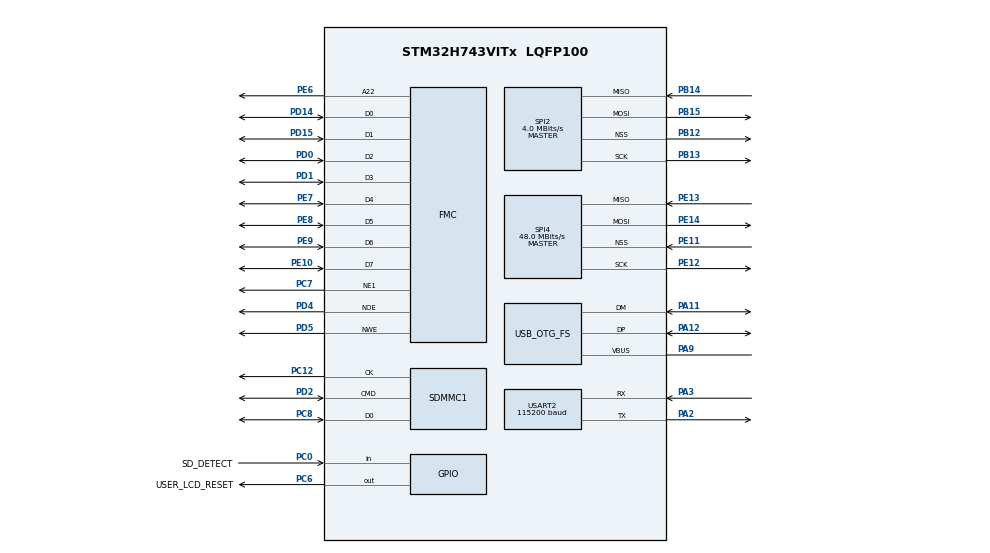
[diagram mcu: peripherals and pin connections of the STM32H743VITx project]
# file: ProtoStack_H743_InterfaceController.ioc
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CORTEX_M7.AccessPermission-Cortex_Memory_Protection_Unit_Region2_Settings=MPU_REGION_FULL_ACCESS
CORTEX_M7.AccessPermission-Cortex_Memory_Protection_Unit_Region3_Settings=MPU_REGION_FULL_ACCESS
CORTEX_M7.BaseAddress-Cortex_Memory_Protection_Unit_Region2_Settings=0x60000000
CORTEX_M7.BaseAddress-Cortex_Memory_Protection_Unit_Region3_Settings=0x24000000
CORTEX_M7.CPU_DCache=Enabled
CORTEX_M7.CPU_ICache=Enabled
CORTEX_M7.DisableExec-Cortex_Memory_Protection_Unit_Region3_Settings=MPU_INSTRUCTION_ACCESS_DISABLE
CORTEX_M7.Enable-Cortex_Memory_Protection_Unit_Region2_Settings=MPU_REGION_ENABLE
CORTEX_M7.Enable-Cortex_Memory_Protection_Unit_Region3_Settings=MPU_REGION_ENABLE
CORTEX_M7.IsBufferable-Cortex_Memory_Protection_Unit_Region2_Settings=MPU_ACCESS_BUFFERABLE
CORTEX_M7.IsBufferable-Cortex_Memory_Protection_Unit_Region3_Settings=MPU_ACCESS_BUFFERABLE
CORTEX_M7.IsShareable-Cortex_Memory_Protection_Unit_Region2_Settings=MPU_ACCESS_SHAREABLE
CORTEX_M7.IsShareable-Cortex_Memory_Protection_Unit_Region3_Settings=MPU_ACCESS_SHAREABLE
CORTEX_M7.MPU_Control=MPU_PRIVILEGED_DEFAULT
CORTEX_M7.Size-Cortex_Memory_Protection_Unit_Region2_Settings=MPU_REGION_SIZE_64MB
CORTEX_M7.Size-Cortex_Memory_Protection_Unit_Region3_Settings=MPU_REGION_SIZE_8KB
Dma.Request0=SPI2_RX
Dma.Request1=SPI2_TX
Dma.Request2=USART2_RX
Dma.Request3=USART2_TX
Dma.Request4=SPI4_RX
Dma.Request5=SPI4_TX
Dma.SPI2_RX.0.Direction=DMA_PERIPH_TO_MEMORY
Dma.SPI2_RX.0.EventEnable=DISABLE
Dma.SPI2_RX.0.FIFOMode=DMA_FIFOMODE_DISABLE
Dma.SPI2_RX.0.Instance=DMA1_Stream2
Dma.SPI2_RX.0.MemDataAlignment=DMA_MDATAALIGN_BYTE
Dma.SPI2_RX.0.MemInc=DMA_MINC_ENABLE
Dma.SPI2_RX.0.Mode=DMA_NORMAL
Dma.SPI2_RX.0.PeriphDataAlignment=DMA_PDATAALIGN_BYTE
Dma.SPI2_RX.0.PeriphInc=DMA_PINC_DISABLE
Dma.SPI2_RX.0.Polarity=HAL_DMAMUX_REQ_GEN_RISING
Dma.SPI2_RX.0.Priority=DMA_PRIORITY_LOW
Dma.SPI2_RX.0.RequestNumber=1
Dma.SPI2_RX.0.SignalID=NONE
Dma.SPI2_RX.0.SyncEnable=DISABLE
Dma.SPI2_RX.0.SyncPolarity=HAL_DMAMUX_SYNC_NO_EVENT
Dma.SPI2_RX.0.SyncRequestNumber=1
Dma.SPI2_RX.0.SyncSignalID=NONE
Dma.SPI2_TX.1.Direction=DMA_MEMORY_TO_PERIPH
Dma.SPI2_TX.1.EventEnable=DISABLE
Dma.SPI2_TX.1.FIFOMode=DMA_FIFOMODE_DISABLE
Dma.SPI2_TX.1.Instance=DMA1_Stream3
Dma.SPI2_TX.1.MemDataAlignment=DMA_MDATAALIGN_BYTE
Dma.SPI2_TX.1.MemInc=DMA_MINC_ENABLE
Dma.SPI2_TX.1.Mode=DMA_NORMAL
Dma.SPI2_TX.1.PeriphDataAlignment=DMA_PDATAALIGN_BYTE
Dma.SPI2_TX.1.PeriphInc=DMA_PINC_DISABLE
Dma.SPI2_TX.1.Polarity=HAL_DMAMUX_REQ_GEN_RISING
Dma.SPI2_TX.1.Priority=DMA_PRIORITY_LOW
Dma.SPI2_TX.1.RequestNumber=1
Dma.SPI2_TX.1.SignalID=NONE
Dma.SPI2_TX.1.SyncEnable=DISABLE
Dma.SPI2_TX.1.SyncPolarity=HAL_DMAMUX_SYNC_NO_EVENT
Dma.SPI2_TX.1.SyncRequestNumber=1
Dma.SPI2_TX.1.SyncSignalID=NONE
Dma.SPI4_RX.4.Direction=DMA_PERIPH_TO_MEMORY
Dma.SPI4_RX.4.EventEnable=DISABLE
Dma.SPI4_RX.4.FIFOMode=DMA_FIFOMODE_DISABLE
Dma.SPI4_RX.4.Instance=DMA1_Stream4
Dma.SPI4_RX.4.MemDataAlignment=DMA_MDATAALIGN_HALFWORD
Dma.SPI4_RX.4.MemInc=DMA_MINC_ENABLE
Dma.SPI4_RX.4.Mode=DMA_CIRCULAR
Dma.SPI4_RX.4.PeriphDataAlignment=DMA_PDATAALIGN_HALFWORD
Dma.SPI4_RX.4.PeriphInc=DMA_PINC_DISABLE
Dma.SPI4_RX.4.Polarity=HAL_DMAMUX_REQ_GEN_RISING
Dma.SPI4_RX.4.Priority=DMA_PRIORITY_LOW
Dma.SPI4_RX.4.RequestNumber=1
Dma.SPI4_RX.4.SignalID=NONE
Dma.SPI4_RX.4.SyncEnable=DISABLE
Dma.SPI4_RX.4.SyncPolarity=HAL_DMAMUX_SYNC_NO_EVENT
Dma.SPI4_RX.4.SyncRequestNumber=1
Dma.SPI4_RX.4.SyncSignalID=NONE
Dma.SPI4_TX.5.Direction=DMA_MEMORY_TO_PERIPH
Dma.SPI4_TX.5.EventEnable=DISABLE
Dma.SPI4_TX.5.FIFOMode=DMA_FIFOMODE_DISABLE
Dma.SPI4_TX.5.Instance=DMA1_Stream5
Dma.SPI4_TX.5.MemDataAlignment=DMA_MDATAALIGN_HALFWORD
Dma.SPI4_TX.5.MemInc=DMA_MINC_ENABLE
Dma.SPI4_TX.5.Mode=DMA_NORMAL
Dma.SPI4_TX.5.PeriphDataAlignment=DMA_PDATAALIGN_HALFWORD
Dma.SPI4_TX.5.PeriphInc=DMA_PINC_DISABLE
Dma.SPI4_TX.5.Polarity=HAL_DMAMUX_REQ_GEN_RISING
Dma.SPI4_TX.5.Priority=DMA_PRIORITY_LOW
Dma.SPI4_TX.5.RequestNumber=1
Dma.SPI4_TX.5.SignalID=NONE
Dma.SPI4_TX.5.SyncEnable=DISABLE
Dma.SPI4_TX.5.SyncPolarity=HAL_DMAMUX_SYNC_NO_EVENT
Dma.SPI4_TX.5.SyncRequestNumber=1
Dma.SPI4_TX.5.SyncSignalID=NONE
Dma.USART2_RX.2.Direction=DMA_PERIPH_TO_MEMORY
Dma.USART2_RX.2.EventEnable=DISABLE
Dma.USART2_RX.2.FIFOMode=DMA_FIFOMODE_DISABLE
Dma.USART2_RX.2.Instance=DMA1_Stream0
Dma.USART2_RX.2.MemDataAlignment=DMA_MDATAALIGN_BYTE
Dma.USART2_RX.2.MemInc=DMA_MINC_ENABLE
Dma.USART2_RX.2.Mode=DMA_CIRCULAR
Dma.USART2_RX.2.PeriphDataAlignment=DMA_PDATAALIGN_BYTE
Dma.USART2_RX.2.PeriphInc=DMA_PINC_DISABLE
Dma.USART2_RX.2.Polarity=HAL_DMAMUX_REQ_GEN_RISING
Dma.USART2_RX.2.Priority=DMA_PRIORITY_LOW
Dma.USART2_RX.2.RequestNumber=1
Dma.USART2_RX.2.SignalID=NONE
Dma.USART2_RX.2.SyncEnable=DISABLE
Dma.USART2_RX.2.SyncPolarity=HAL_DMAMUX_SYNC_NO_EVENT
Dma.USART2_RX.2.SyncRequestNumber=1
Dma.USART2_RX.2.SyncSignalID=NONE
Dma.USART2_TX.3.Direction=DMA_MEMORY_TO_PERIPH
Dma.USART2_TX.3.EventEnable=DISABLE
Dma.USART2_TX.3.FIFOMode=DMA_FIFOMODE_DISABLE
Dma.USART2_TX.3.Instance=DMA1_Stream1
Dma.USART2_TX.3.MemDataAlignment=DMA_MDATAALIGN_BYTE
Dma.USART2_TX.3.MemInc=DMA_MINC_ENABLE
Dma.USART2_TX.3.Mode=DMA_NORMAL
Dma.USART2_TX.3.PeriphDataAlignment=DMA_PDATAALIGN_BYTE
Dma.USART2_TX.3.PeriphInc=DMA_PINC_DISABLE
Dma.USART2_TX.3.Polarity=HAL_DMAMUX_REQ_GEN_RISING
Dma.USART2_TX.3.Priority=DMA_PRIORITY_LOW
Dma.USART2_TX.3.RequestNumber=1
Dma.USART2_TX.3.SignalID=NONE
Dma.USART2_TX.3.SyncEnable=DISABLE
Dma.USART2_TX.3.SyncPolarity=HAL_DMAMUX_SYNC_NO_EVENT
Dma.USART2_TX.3.SyncRequestNumber=1
Dma.USART2_TX.3.SyncSignalID=NONE
FATFS.BSP.number=1
FATFS._FS_RPATH=2
FATFS._USE_EXPAND=1
FATFS._USE_FIND=1
FATFS._USE_LFN=3
FATFS0.BSP.STBoard=false
FATFS0.BSP.api=Unknown
FATFS0.BSP.instance=PC0
FATFS0.BSP.ip=GPIO
FATFS0.BSP.mode=Input
FATFS0.BSP.name=Detect_SDIO
FATFS0.BSP.solution=PC0
FMC.AddressSetupTime1=8
FMC.BusTurnAroundDuration1=8
FMC.DataSetupTime1=16
FREERTOS.Queues01=UpdateGUIQueue,16,struct UPDATEGUIQUEUE_OBJ_t,0,Dynamic,NULL,NULL;ReadWriteUIQueue,16,struct READWRITEUIQUEUE_OBJ_t,0,Dynamic,NULL,NULL;UpdateAudioParamsQueue,16,struct UPDATEAUDIOPARAMS_OBJ_t,0,Dynamic,NULL,NULL
FREERTOS.Tasks01=defaultTask,24,128,StartDefaultTask,Default,NULL,Dynamic,NULL,NULL;TouchGFXUpdateTask,24,1024,StartTouchGFXUpdateTask,Default,NULL,Dynamic,NULL,NULL;VSyncTask,24,512,StartVSyncTask,Default,NULL,Dynamic,NULL,NULL;ReadWriteUITask,24,512,StartReadWriteUITask,Default,NULL,Dynamic,NULL,NULL;UpdateFromUITask,24,512,StartUpdateFromUITask,Default,NULL,Dynamic,NULL,NULL
FREERTOS.configGENERATE_RUN_TIME_STATS=1
FREERTOS.configMAX_TASK_NAME_LEN=32
FREERTOS.configRECORD_STACK_HIGH_ADDRESS=1
FREERTOS.configTOTAL_HEAP_SIZE=16384
FREERTOS.configUSE_NEWLIB_REENTRANT=1
FREERTOS.configUSE_STATS_FORMATTING_FUNCTIONS=1
Mcu.Family=STM32H7
Mcu.Name=STM32H743VITx
Mcu.Package=LQFP100
NVIC.DMA1_Stream0_IRQn=true\:5\:0\:false\:false\:true\:true\:false\:true\:true
NVIC.DMA1_Stream1_IRQn=true\:5\:0\:false\:false\:true\:true\:false\:true\:true
NVIC.DMA1_Stream2_IRQn=true\:5\:0\:false\:false\:true\:true\:false\:true\:true
NVIC.DMA1_Stream3_IRQn=true\:5\:0\:false\:false\:true\:true\:false\:true\:true
NVIC.DMA1_Stream4_IRQn=true\:5\:0\:false\:false\:true\:true\:false\:true\:true
NVIC.DMA1_Stream5_IRQn=true\:5\:0\:false\:false\:true\:true\:false\:true\:true
NVIC.OTG_FS_IRQn=true\:5\:0\:false\:false\:true\:true\:true\:true\:true
NVIC.PriorityGroup=NVIC_PRIORITYGROUP_4
NVIC.SDMMC1_IRQn=true\:5\:0\:false\:false\:true\:true\:true\:true\:true
NVIC.SPI2_IRQn=true\:5\:0\:false\:false\:true\:true\:true\:true\:true
NVIC.SPI4_IRQn=true\:5\:0\:false\:false\:true\:true\:true\:true\:true
NVIC.TIM2_IRQn=true\:0\:0\:true\:false\:true\:false\:false\:true\:true
NVIC.TIM6_DAC_IRQn=true\:5\:0\:false\:false\:true\:true\:true\:true\:true
NVIC.TimeBase=TIM2_IRQn
NVIC.TimeBaseIP=TIM2
NVIC.USART2_IRQn=true\:15\:0\:true\:false\:true\:true\:true\:true\:true
PA11.GPIO_Speed=GPIO_SPEED_FREQ_VERY_HIGH
PA11.Mode=Device_Only
PA11.Signal=USB_OTG_FS_DM
PA12.GPIO_Speed=GPIO_SPEED_FREQ_VERY_HIGH
PA12.Mode=Device_Only
PA12.Signal=USB_OTG_FS_DP
PA13\ (JTMS/SWDIO).Mode=Trace_Asynchronous_SW
PA13\ (JTMS/SWDIO).Signal=DEBUG_JTMS-SWDIO
PA14\ (JTCK/SWCLK).Mode=Trace_Asynchronous_SW
PA14\ (JTCK/SWCLK).Signal=DEBUG_JTCK-SWCLK
PA2.GPIO_Speed=GPIO_SPEED_FREQ_LOW
PA2.Mode=Asynchronous
PA2.Signal=USART2_TX
PA3.GPIO_Speed=GPIO_SPEED_FREQ_LOW
PA3.Mode=Asynchronous
PA3.Signal=USART2_RX
PA9.Mode=Activate_VBUS
PA9.Signal=USB_OTG_FS_VBUS
PB12.Mode=NSS_Signal_Hard_Output
PB12.Signal=SPI2_NSS
PB13.Mode=Full_Duplex_Master
PB13.Signal=SPI2_SCK
PB14.Mode=Full_Duplex_Master
PB14.Signal=SPI2_MISO
PB15.Mode=Full_Duplex_Master
PB15.Signal=SPI2_MOSI
PB3\ (JTDO/TRACESWO).Mode=Trace_Asynchronous_SW
PB3\ (JTDO/TRACESWO).Signal=DEBUG_JTDO-SWO
PC0.GPIO_Label=SD_DETECT
PC0.GPIO_PuPd=GPIO_PULLUP
PC0.Signal=GPIO_Input
PC12.GPIO_PuPd=GPIO_PULLUP
PC12.Mode=SD_1_bit
PC12.Signal=SDMMC1_CK
PC6.GPIO_Label=USER_LCD_RESET
PC6.PinState=GPIO_PIN_SET
PC6.Signal=GPIO_Output
PC7.Mode=NorPsramChipSelect1_1
PC7.Signal=FMC_NE1
PC8.GPIO_PuPd=GPIO_PULLUP
PC8.Mode=SD_1_bit
PC8.Signal=SDMMC1_D0
PD0.Signal=FMC_D2_DA2
PD1.Signal=FMC_D3_DA3
PD14.Signal=FMC_D0_DA0
PD15.Signal=FMC_D1_DA1
PD2.GPIO_PuPd=GPIO_PULLUP
PD2.Mode=SD_1_bit
PD2.Signal=SDMMC1_CMD
PD4.Signal=FMC_NOE
PD5.Signal=FMC_NWE
PD7.GPIO_Speed=GPIO_SPEED_FREQ_LOW
PD7.Signal=USART2_CK
PE10.Signal=FMC_D7_DA7
PE11.Mode=NSS_Signal_Hard_Input
PE11.Signal=SPI4_NSS
PE12.Mode=Full_Duplex_Master
PE12.Signal=SPI4_SCK
PE13.Mode=Full_Duplex_Master
PE13.Signal=SPI4_MISO
PE14.Mode=Full_Duplex_Master
PE14.Signal=SPI4_MOSI
PE6.Signal=FMC_A22
PE7.Signal=FMC_D4_DA4
PE8.Signal=FMC_D5_DA5
PE9.Signal=FMC_D6_DA6
PH0-OSC_IN\ (PH0).Mode=HSE-External-Oscillator
PH0-OSC_IN\ (PH0).Signal=RCC_OSC_IN
PH1-OSC_OUT\ (PH1).Mode=HSE-External-Oscillator
PH1-OSC_OUT\ (PH1).Signal=RCC_OSC_OUT
ProjectManager.HeapSize=0x400
ProjectManager.StackSize=0x800
ProjectManager.TargetToolchain=STM32CubeIDE
RCC.ADCFreq_Value=192000000
RCC.APB1Freq_Value=120000000
RCC.APB2Freq_Value=120000000
RCC.APB3Freq_Value=120000000
RCC.APB4Freq_Value=120000000
RCC.CortexFreq_Value=480000000
RCC.D1PPRE=RCC_APB3_DIV2
RCC.D2PPRE1=RCC_APB1_DIV2
RCC.D2PPRE2=RCC_APB2_DIV2
RCC.D3PPRE=RCC_APB4_DIV2
RCC.DIVM1=4
RCC.DIVM2=8
RCC.DIVM3=16
RCC.DIVN1=160
RCC.DIVN2=128
RCC.DIVN3=128
RCC.DIVQ1=20
RCC.HCLKFreq_Value=240000000
RCC.HPRE=RCC_HCLK_DIV2
RCC.HSE_VALUE=24000000
RCC.PLLSourceVirtual=RCC_PLLSOURCE_HSE
RCC.SPI123CLockSelection=RCC_SPI123CLKSOURCE_CLKP
RCC.SYSCLKFreq_VALUE=480000000
RCC.SYSCLKSource=RCC_SYSCLKSOURCE_PLLCLK
RCC.Spi45ClockSelection=RCC_SPI45CLKSOURCE_PLL3
RCC.USBCLockSelection=RCC_USBCLKSOURCE_HSI48
RCC.USBFreq_Value=48000000
SDMMC1.ClockDiv=1
SH.FMC_A22.0=FMC_A22,A22_1
SH.FMC_D0_DA0.0=FMC_D0,8b-d1
SH.FMC_D1_DA1.0=FMC_D1,8b-d1
SH.FMC_D2_DA2.0=FMC_D2,8b-d1
SH.FMC_D3_DA3.0=FMC_D3,8b-d1
SH.FMC_D4_DA4.0=FMC_D4,8b-d1
SH.FMC_D5_DA5.0=FMC_D5,8b-d1
SH.FMC_D6_DA6.0=FMC_D6,8b-d1
SH.FMC_D7_DA7.0=FMC_D7,8b-d1
SH.FMC_NOE.0=FMC_NOE,Lcd1
SH.FMC_NWE.0=FMC_NWE,Lcd1
SPI2.BaudRatePrescaler=SPI_BAUDRATEPRESCALER_16
SPI2.CalculateBaudRate=4.0 MBits/s
SPI2.DataSize=SPI_DATASIZE_8BIT
SPI2.Direction=SPI_DIRECTION_2LINES
SPI2.Mode=SPI_MODE_MASTER
SPI2.NSSPolarity=SPI_NSS_POLARITY_HIGH
SPI2.VirtualNSS=VM_NSSHARD
SPI2.VirtualType=VM_MASTER
SPI4.CalculateBaudRate=48.0 MBits/s
SPI4.DataSize=SPI_DATASIZE_16BIT
SPI4.Direction=SPI_DIRECTION_2LINES
SPI4.Mode=SPI_MODE_MASTER
SPI4.VirtualNSS=VM_NSSHARD
SPI4.VirtualType=VM_MASTER
STMicroelectronics.X-CUBE-TOUCHGFX.4.21.3.ApplicationCcGraphicsJjApplication=TouchGFXOoGenerator
STMicroelectronics.X-CUBE-TOUCHGFX.4.21.3.tgfx_address1=0x60000000
STMicroelectronics.X-CUBE-TOUCHGFX.4.21.3.tgfx_block_size=15360
STMicroelectronics.X-CUBE-TOUCHGFX.4.21.3.tgfx_buffering_strategy=Partial
STMicroelectronics.X-CUBE-TOUCHGFX.4.21.3.tgfx_custom_height=240
STMicroelectronics.X-CUBE-TOUCHGFX.4.21.3.tgfx_custom_width=320
STMicroelectronics.X-CUBE-TOUCHGFX.4.21.3.tgfx_display_interface=disp_custom
STMicroelectronics.X-CUBE-TOUCHGFX.4.21.3.tgfx_hardware_accelerator=dma_none
STMicroelectronics.X-CUBE-TOUCHGFX.4.21.3.tgfx_location=By Address
STMicroelectronics.X-CUBE-TOUCHGFX.4.21.3.tgfx_number_of_blocks=4
STMicroelectronics.X-CUBE-TOUCHGFX.4.21.3_IsPackSelfContextualization=true
TIM6.Period=99
TIM6.Prescaler=240
USART2.BaudRate=115200
USART2.RxPinLevelInvertParam=ADVFEATURE_RXINV_DISABLE
USART2.TxPinLevelInvertParam=ADVFEATURE_TXINV_DISABLE
USART2.VirtualMode-Asynchronous=VM_ASYNC
USB_DEVICE.CLASS_NAME_FS=MSC
USB_DEVICE.MSC_MEDIA_PACKET-MSC_FS=0x1000
USB_DEVICE.VirtualMode-MSC_FS=Msc
USB_DEVICE.VirtualModeFS=Msc_FS
USB_OTG_FS.VirtualMode=Device_Only
VP_CRC_VS_CRC.Mode=CRC_Activate
VP_FATFS_VS_SDIO.Mode=SDIO
VP_FREERTOS_VS_CMSIS_V2.Mode=CMSIS_V2
VP_STMicroelectronics.X-CUBE-TOUCHGFX_VS_GraphicsJjApplication_4.21.3.Mode=GraphicsJjApplication
VP_SYS_VS_tim2.Mode=TIM2
VP_TIM6_VS_ClockSourceINT.Mode=Enable_Timer
VP_USB_DEVICE_VS_USB_DEVICE_MSC_FS.Mode=MSC_FS
board=custom

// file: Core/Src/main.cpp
/* USER CODE BEGIN Header */
/**
  ******************************************************************************
  * @file           : main.c
  * @brief          : Main program body
  ******************************************************************************
  * @attention
  *
  * Copyright (c) 2023 STMicroelectronics.
  * All rights reserved.
  *
  * This software is licensed under terms that can be found in the LICENSE file
  * in the root directory of this software component.
  * If no LICENSE file comes with this software, it is provided AS-IS.
  *
  ******************************************************************************
  */
/* USER CODE END Header */
#include "main.h"
#include "cmsis_os.h"
#include "crc.h"
#include "dma.h"
#include "fatfs.h"
#include "sdmmc.h"
#include "spi.h"
#include "tim.h"
#include "usart.h"
#include "gpio.h"
#include "fmc.h"
#include "app_touchgfx.h"

/* USER CODE BEGIN Includes */
#include "../../Drivers/ili9341/ili9341.h"
#include "../../Drivers/UI/ui_adapter_reg.h"
#include "../../Drivers/UI/UARTadapter.h"
#include <gui/effectsettings_screen/EffectSettingsView.hpp>
/* USER CODE END Includes */

void SystemClock_Config(void);
void PeriphCommonClock_Config(void);
static void MPU_Config(void);
void MX_FREERTOS_Init(void);

int main(void)
{

  /* MPU Configuration--------------------------------------------------------*/
  MPU_Config();

  /* Enable I-Cache---------------------------------------------------------*/
  SCB_EnableICache();

  /* Enable D-Cache---------------------------------------------------------*/
  SCB_EnableDCache();

  /* MCU Configuration--------------------------------------------------------*/

  /* Reset of all peripherals, Initializes the Flash interface and the Systick. */
  HAL_Init();

  /* Configure the system clock */
  SystemClock_Config();

/* Configure the peripherals common clocks */
  PeriphCommonClock_Config();

  /* Initialize all configured peripherals */
  MX_GPIO_Init();
  MX_DMA_Init();
  MX_USART2_UART_Init();
  MX_SPI2_Init();
  MX_SPI4_Init();
  MX_CRC_Init();
  MX_TIM6_Init();
  MX_SDMMC1_SD_Init();
  MX_FMC_Init();
  MX_FATFS_Init();
  MX_TouchGFX_Init();
  /* Call PreOsInit function */
  MX_TouchGFX_PreOSInit();
  /* USER CODE BEGIN 2 */
  ili9341_Init();

  UIadapter_Init(&UIadapterReg);  // spi buttons
  UARTadapter_Init(&audio_uart_adapter);  // uart interface to audio mcu

  /* USER CODE END 2 */

  /* Init scheduler */
  osKernelInitialize();  /* Call init function for freertos objects (in freertos.c) */
  MX_FREERTOS_Init();

  /* Start scheduler */
  osKernelStart();

  /* We should never get here as control is now taken by the scheduler */
  /* Infinite loop */
  while (1)
  {

  }
}

void SystemClock_Config(void)
{
  RCC_OscInitTypeDef RCC_OscInitStruct = {0};
  RCC_ClkInitTypeDef RCC_ClkInitStruct = {0};

  /** Supply configuration update enable
  */
  HAL_PWREx_ConfigSupply(PWR_LDO_SUPPLY);

  /** Configure the main internal regulator output voltage
  */
  __HAL_PWR_VOLTAGESCALING_CONFIG(PWR_REGULATOR_VOLTAGE_SCALE1);

  while(!__HAL_PWR_GET_FLAG(PWR_FLAG_VOSRDY)) {}

  __HAL_RCC_SYSCFG_CLK_ENABLE();
  __HAL_PWR_VOLTAGESCALING_CONFIG(PWR_REGULATOR_VOLTAGE_SCALE0);

  while(!__HAL_PWR_GET_FLAG(PWR_FLAG_VOSRDY)) {}

  /** Macro to configure the PLL clock source
  */
  __HAL_RCC_PLL_PLLSOURCE_CONFIG(RCC_PLLSOURCE_HSE);

  /** Initializes the RCC Oscillators according to the specified parameters
  * in the RCC_OscInitTypeDef structure.
  */
  RCC_OscInitStruct.OscillatorType = RCC_OSCILLATORTYPE_HSI48|RCC_OSCILLATORTYPE_HSI
                              |RCC_OSCILLATORTYPE_HSE;
  RCC_OscInitStruct.HSEState = RCC_HSE_ON;
  RCC_OscInitStruct.HSIState = RCC_HSI_DIV1;
  RCC_OscInitStruct.HSICalibrationValue = RCC_HSICALIBRATION_DEFAULT;
  RCC_OscInitStruct.HSI48State = RCC_HSI48_ON;
  RCC_OscInitStruct.PLL.PLLState = RCC_PLL_ON;
  RCC_OscInitStruct.PLL.PLLSource = RCC_PLLSOURCE_HSE;
  RCC_OscInitStruct.PLL.PLLM = 4;
  RCC_OscInitStruct.PLL.PLLN = 160;
  RCC_OscInitStruct.PLL.PLLP = 2;
  RCC_OscInitStruct.PLL.PLLQ = 20;
  RCC_OscInitStruct.PLL.PLLR = 2;
  RCC_OscInitStruct.PLL.PLLRGE = RCC_PLL1VCIRANGE_2;
  RCC_OscInitStruct.PLL.PLLVCOSEL = RCC_PLL1VCOWIDE;
  RCC_OscInitStruct.PLL.PLLFRACN = 0;
  if (HAL_RCC_OscConfig(&RCC_OscInitStruct) != HAL_OK)
  {
    Error_Handler();
  }

  /** Initializes the CPU, AHB and APB buses clocks
  */
  RCC_ClkInitStruct.ClockType = RCC_CLOCKTYPE_HCLK|RCC_CLOCKTYPE_SYSCLK
                              |RCC_CLOCKTYPE_PCLK1|RCC_CLOCKTYPE_PCLK2
                              |RCC_CLOCKTYPE_D3PCLK1|RCC_CLOCKTYPE_D1PCLK1;
  RCC_ClkInitStruct.SYSCLKSource = RCC_SYSCLKSOURCE_PLLCLK;
  RCC_ClkInitStruct.SYSCLKDivider = RCC_SYSCLK_DIV1;
  RCC_ClkInitStruct.AHBCLKDivider = RCC_HCLK_DIV2;
  RCC_ClkInitStruct.APB3CLKDivider = RCC_APB3_DIV2;
  RCC_ClkInitStruct.APB1CLKDivider = RCC_APB1_DIV2;
  RCC_ClkInitStruct.APB2CLKDivider = RCC_APB2_DIV2;
  RCC_ClkInitStruct.APB4CLKDivider = RCC_APB4_DIV2;

  if (HAL_RCC_ClockConfig(&RCC_ClkInitStruct, FLASH_LATENCY_4) != HAL_OK)
  {
    Error_Handler();
  }
}

void PeriphCommonClock_Config(void)
{
  RCC_PeriphCLKInitTypeDef PeriphClkInitStruct = {0};

  /** Initializes the peripherals clock
  */
  PeriphClkInitStruct.PeriphClockSelection = RCC_PERIPHCLK_CKPER;
  PeriphClkInitStruct.CkperClockSelection = RCC_CLKPSOURCE_HSI;
  if (HAL_RCCEx_PeriphCLKConfig(&PeriphClkInitStruct) != HAL_OK)
  {
    Error_Handler();
  }
}

/* USER CODE BEGIN 4 */
//void HAL_UART_ErrorCallback(UART_HandleTypeDef *huart)
//{
//    HAL_UART_DeInit(&huart2);
//    HAL_UART_Receive_DMA(&huart2, audioParamsRXbuf, 4);
//}

/* USER CODE END 4 */

/* MPU Configuration */

void MPU_Config(void)
{
  MPU_Region_InitTypeDef MPU_InitStruct = {0};

  /* Disables the MPU */
  HAL_MPU_Disable();

  /** Initializes and configures the Region and the memory to be protected
  */
  MPU_InitStruct.Enable = MPU_REGION_ENABLE;
  MPU_InitStruct.Number = MPU_REGION_NUMBER2;
  MPU_InitStruct.BaseAddress = 0x60000000;
  MPU_InitStruct.Size = MPU_REGION_SIZE_64MB;
  MPU_InitStruct.SubRegionDisable = 0x0;
  MPU_InitStruct.TypeExtField = MPU_TEX_LEVEL0;
  MPU_InitStruct.AccessPermission = MPU_REGION_FULL_ACCESS;
  MPU_InitStruct.DisableExec = MPU_INSTRUCTION_ACCESS_ENABLE;
  MPU_InitStruct.IsShareable = MPU_ACCESS_SHAREABLE;
  MPU_InitStruct.IsCacheable = MPU_ACCESS_NOT_CACHEABLE;
  MPU_InitStruct.IsBufferable = MPU_ACCESS_BUFFERABLE;

  HAL_MPU_ConfigRegion(&MPU_InitStruct);

  /** Initializes and configures the Region and the memory to be protected
  */
  MPU_InitStruct.Number = MPU_REGION_NUMBER3;
  MPU_InitStruct.BaseAddress = 0x24000000;
  MPU_InitStruct.Size = MPU_REGION_SIZE_8KB;
  MPU_InitStruct.DisableExec = MPU_INSTRUCTION_ACCESS_DISABLE;

  HAL_MPU_ConfigRegion(&MPU_InitStruct);
  /* Enables the MPU */
  HAL_MPU_Enable(MPU_PRIVILEGED_DEFAULT);

}

void HAL_TIM_PeriodElapsedCallback(TIM_HandleTypeDef *htim)
{
  if (htim->Instance == TIM2) {
    HAL_IncTick();
  }
}

void Error_Handler(void)
{
  __disable_irq();
  while (1)
  {
  }
}
